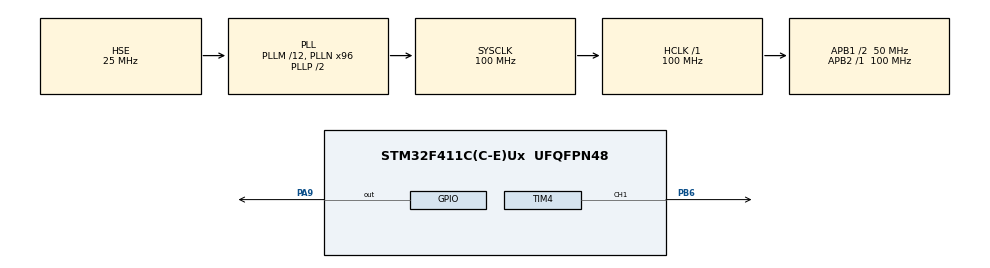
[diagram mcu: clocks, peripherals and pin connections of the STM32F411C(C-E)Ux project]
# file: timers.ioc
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Mcu.Family=STM32F4
Mcu.Name=STM32F411C(C-E)Ux
Mcu.Package=UFQFPN48
NVIC.PriorityGroup=NVIC_PRIORITYGROUP_4
NVIC.TIM2_IRQn=true\:0\:0\:false\:false\:true\:true\:true\:true
PA13.Mode=Serial_Wire
PA13.Signal=SYS_JTMS-SWDIO
PA14.Mode=Serial_Wire
PA14.Signal=SYS_JTCK-SWCLK
PA9.Signal=GPIO_Output
PB6.Signal=S_TIM4_CH1
PH0\ -\ OSC_IN.Mode=HSE-External-Oscillator
PH0\ -\ OSC_IN.Signal=RCC_OSC_IN
PH1\ -\ OSC_OUT.Mode=HSE-External-Oscillator
PH1\ -\ OSC_OUT.Signal=RCC_OSC_OUT
ProjectManager.HeapSize=0x200
ProjectManager.StackSize=0x400
ProjectManager.TargetToolchain=STM32CubeIDE
RCC.48MHZClocksFreq_Value=50000000
RCC.AHBFreq_Value=100000000
RCC.APB1CLKDivider=RCC_HCLK_DIV2
RCC.APB1Freq_Value=50000000
RCC.APB1TimFreq_Value=100000000
RCC.APB2Freq_Value=100000000
RCC.APB2TimFreq_Value=100000000
RCC.CortexFreq_Value=100000000
RCC.HCLKFreq_Value=100000000
RCC.HSE_VALUE=25000000
RCC.HSI_VALUE=16000000
RCC.LSE_VALUE=32768
RCC.PLLM=12
RCC.PLLN=96
RCC.PLLSourceVirtual=RCC_PLLSOURCE_HSE
RCC.SYSCLKFreq_VALUE=100000000
RCC.SYSCLKSource=RCC_SYSCLKSOURCE_PLLCLK
RCC.VCOOutputFreq_Value=200000000
SH.S_TIM4_CH1.0=TIM4_CH1,PWM Generation1 CH1
TIM2.Period=50000-1
TIM2.Prescaler=1000 -1 
TIM3.ClockDivision=TIM_CLOCKDIVISION_DIV1
TIM3.Prescaler=100-1
TIM4.Channel-PWM\ Generation1\ CH1=TIM_CHANNEL_1
TIM4.Period=50000-1
TIM4.Prescaler=4 - 1
VP_TIM2_VS_ClockSourceINT.Mode=Internal
VP_TIM3_VS_ClockSourceINT.Mode=Internal
VP_TIM4_VS_ClockSourceINT.Mode=Internal
board=custom

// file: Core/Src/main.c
/* USER CODE BEGIN Header */
/**
  ******************************************************************************
  * @file           : main.c
  * @brief          : Main program body
  ******************************************************************************
  * @attention
  *
  * Copyright (c) 2025 STMicroelectronics.
  * All rights reserved.
  *
  * This software is licensed under terms that can be found in the LICENSE file
  * in the root directory of this software component.
  * If no LICENSE file comes with this software, it is provided AS-IS.
  *
  ******************************************************************************
  */
/* USER CODE END Header */
#include "main.h"
#include<string.h>

TIM_HandleTypeDef htim2;
TIM_HandleTypeDef htim3;
TIM_HandleTypeDef htim4;

/* USER CODE BEGIN PV */
void delay_us(uint16_t time){
	__HAL_TIM_SET_COUNTER(&htim3,0);
	while(__HAL_TIM_GET_COUNTER(&htim3)<time);

}
void HAL_TIM_PeriodElapsedCallback(TIM_HandleTypeDef *htim){
	  if(htim->Instance == TIM2){
		  HAL_GPIO_TogglePin(GPIOA, GPIO_PIN_9);
	  }

 }

/* USER CODE END PV */

void SystemClock_Config(void);
static void MX_GPIO_Init(void);
static void MX_TIM2_Init(void);
static void MX_TIM3_Init(void);
static void MX_TIM4_Init(void);

/* USER CODE BEGIN 0 */
/* USER CODE BEGIN 2 */

/* USER CODE END 0 */

int main(void)
{

  /* MCU Configuration--------------------------------------------------------*/

  /* Reset of all peripherals, Initializes the Flash interface and the Systick. */
  HAL_Init();

  /* Configure the system clock */
  SystemClock_Config();

  /* Initialize all configured peripherals */
  MX_GPIO_Init();
  MX_TIM2_Init();
  MX_TIM3_Init();
  MX_TIM4_Init();
  HAL_TIM_PWM_Start(&htim4, TIM_CHANNEL_1);
  __HAL_TIM_SET_COMPARE(&htim4,TIM_CHANNEL_1,0);
  /* USER CODE BEGIN 2 */

/* USER CODE END 0 */

/**
  * @brief  The application entry point.
  * @retval int
  */
int main(void)
{

  /* USER CODE BEGIN 1 */

  /* USER CODE END 1 */

  /* MCU Configuration--------------------------------------------------------*/

  /* Reset of all peripherals, Initializes the Flash interface and the Systick. */
  HAL_Init();

  /* USER CODE BEGIN Init */

  /* USER CODE END Init */

  /* Configure the system clock */
  SystemClock_Config();

  /* USER CODE BEGIN SysInit */

  /* USER CODE END SysInit */

  /* Initialize all configured peripherals */
  MX_GPIO_Init();
  MX_TIM2_Init();
  MX_TIM3_Init();
  HAL_TIM_Base_Start(&htim3);
  /* USER CODE BEGIN 2 */
 void HAL_TIM_PeriodElapsedCallback(TIM_HandleTypeDef *htim){
	  if(htim->Instance == TIM2){
		  HAL_GPIO_TogglePin(GPIOA, GPIO_PIN_9);
	  }

 }

/* USER CODE END 0 */

/**
  * @brief  The application entry point.
  * @retval int
  */
int main(void)
{

  /* USER CODE BEGIN 1 */

  /* USER CODE END 1 */

  /* MCU Configuration--------------------------------------------------------*/

  /* Reset of all peripherals, Initializes the Flash interface and the Systick. */
  HAL_Init();

  /* USER CODE BEGIN Init */

  /* USER CODE END Init */

  /* Configure the system clock */
  SystemClock_Config();

  /* USER CODE BEGIN SysInit */

  /* USER CODE END SysInit */

  /* Initialize all configured peripherals */
  MX_GPIO_Init();
  MX_TIM2_Init();
  HAL_TIM_Base_Start_IT(&htim2);
uint16_t duty;

  /* USER CODE END 2 */

  /* Infinite loop */
  /* USER CODE BEGIN WHILE */
  while (1)
  {
	  while(duty<50000){
	  __HAL_TIM_SET_COMPARE(&htim4,TIM_CHANNEL_1,duty);
	  duty+=1000;
	  }
  while(duty >0){
	  __HAL_TIM_SET_COMPARE(&htim4,TIM_CHANNEL_1,duty);
			  duty-=1000;

  }

  }
  }
    /* USER CODE END WHILE */

  }
}

void SystemClock_Config(void)
{
  RCC_OscInitTypeDef RCC_OscInitStruct = {0};
  RCC_ClkInitTypeDef RCC_ClkInitStruct = {0};

  /** Configure the main internal regulator output voltage
  */
  __HAL_RCC_PWR_CLK_ENABLE();
  __HAL_PWR_VOLTAGESCALING_CONFIG(PWR_REGULATOR_VOLTAGE_SCALE1);

  /** Initializes the RCC Oscillators according to the specified parameters
  * in the RCC_OscInitTypeDef structure.
  */
  RCC_OscInitStruct.OscillatorType = RCC_OSCILLATORTYPE_HSE;
  RCC_OscInitStruct.HSEState = RCC_HSE_ON;
  RCC_OscInitStruct.PLL.PLLState = RCC_PLL_ON;
  RCC_OscInitStruct.PLL.PLLSource = RCC_PLLSOURCE_HSE;
  RCC_OscInitStruct.PLL.PLLM = 12;
  RCC_OscInitStruct.PLL.PLLN = 96;
  RCC_OscInitStruct.PLL.PLLP = RCC_PLLP_DIV2;
  RCC_OscInitStruct.PLL.PLLQ = 4;
  if (HAL_RCC_OscConfig(&RCC_OscInitStruct) != HAL_OK)
  {
    Error_Handler();
  }

  /** Initializes the CPU, AHB and APB buses clocks
  */
  RCC_ClkInitStruct.ClockType = RCC_CLOCKTYPE_HCLK|RCC_CLOCKTYPE_SYSCLK
                              |RCC_CLOCKTYPE_PCLK1|RCC_CLOCKTYPE_PCLK2;
  RCC_ClkInitStruct.SYSCLKSource = RCC_SYSCLKSOURCE_PLLCLK;
  RCC_ClkInitStruct.AHBCLKDivider = RCC_SYSCLK_DIV1;
  RCC_ClkInitStruct.APB1CLKDivider = RCC_HCLK_DIV2;
  RCC_ClkInitStruct.APB2CLKDivider = RCC_HCLK_DIV1;

  if (HAL_RCC_ClockConfig(&RCC_ClkInitStruct, FLASH_LATENCY_3) != HAL_OK)
  {
    Error_Handler();
  }
}

static void MX_TIM2_Init(void)
{

  TIM_ClockConfigTypeDef sClockSourceConfig = {0};
  TIM_MasterConfigTypeDef sMasterConfig = {0};

  htim2.Instance = TIM2;
  htim2.Init.Prescaler = 1000 -1 ;
  htim2.Init.CounterMode = TIM_COUNTERMODE_UP;
  htim2.Init.Period = 50000-1;
  htim2.Init.ClockDivision = TIM_CLOCKDIVISION_DIV1;
  htim2.Init.AutoReloadPreload = TIM_AUTORELOAD_PRELOAD_DISABLE;
  if (HAL_TIM_Base_Init(&htim2) != HAL_OK)
  {
    Error_Handler();
  }
  sClockSourceConfig.ClockSource = TIM_CLOCKSOURCE_INTERNAL;
  if (HAL_TIM_ConfigClockSource(&htim2, &sClockSourceConfig) != HAL_OK)
  {
    Error_Handler();
  }
  sMasterConfig.MasterOutputTrigger = TIM_TRGO_RESET;
  sMasterConfig.MasterSlaveMode = TIM_MASTERSLAVEMODE_DISABLE;
  if (HAL_TIMEx_MasterConfigSynchronization(&htim2, &sMasterConfig) != HAL_OK)
  {
    Error_Handler();
  }

}

static void MX_TIM3_Init(void)
{

  TIM_ClockConfigTypeDef sClockSourceConfig = {0};
  TIM_MasterConfigTypeDef sMasterConfig = {0};

  htim3.Instance = TIM3;
  htim3.Init.Prescaler = 100-1;
  htim3.Init.CounterMode = TIM_COUNTERMODE_UP;
  htim3.Init.Period = 65535;
  htim3.Init.ClockDivision = TIM_CLOCKDIVISION_DIV1;
  htim3.Init.AutoReloadPreload = TIM_AUTORELOAD_PRELOAD_DISABLE;
  if (HAL_TIM_Base_Init(&htim3) != HAL_OK)
  {
    Error_Handler();
  }
  sClockSourceConfig.ClockSource = TIM_CLOCKSOURCE_INTERNAL;
  if (HAL_TIM_ConfigClockSource(&htim3, &sClockSourceConfig) != HAL_OK)
  {
    Error_Handler();
  }
  sMasterConfig.MasterOutputTrigger = TIM_TRGO_RESET;
  sMasterConfig.MasterSlaveMode = TIM_MASTERSLAVEMODE_DISABLE;
  if (HAL_TIMEx_MasterConfigSynchronization(&htim3, &sMasterConfig) != HAL_OK)
  {
    Error_Handler();
  }

}

static void MX_TIM4_Init(void)
{

  TIM_ClockConfigTypeDef sClockSourceConfig = {0};
  TIM_MasterConfigTypeDef sMasterConfig = {0};
  TIM_OC_InitTypeDef sConfigOC = {0};

  htim4.Instance = TIM4;
  htim4.Init.Prescaler = 4 - 1;
  htim4.Init.CounterMode = TIM_COUNTERMODE_UP;
  htim4.Init.Period = 50000-1;
  htim4.Init.ClockDivision = TIM_CLOCKDIVISION_DIV1;
  htim4.Init.AutoReloadPreload = TIM_AUTORELOAD_PRELOAD_DISABLE;
  if (HAL_TIM_Base_Init(&htim4) != HAL_OK)
  {
    Error_Handler();
  }
  sClockSourceConfig.ClockSource = TIM_CLOCKSOURCE_INTERNAL;
  if (HAL_TIM_ConfigClockSource(&htim4, &sClockSourceConfig) != HAL_OK)
  {
    Error_Handler();
  }
  if (HAL_TIM_PWM_Init(&htim4) != HAL_OK)
  {
    Error_Handler();
  }
  sMasterConfig.MasterOutputTrigger = TIM_TRGO_RESET;
  sMasterConfig.MasterSlaveMode = TIM_MASTERSLAVEMODE_DISABLE;
  if (HAL_TIMEx_MasterConfigSynchronization(&htim4, &sMasterConfig) != HAL_OK)
  {
    Error_Handler();
  }
  sConfigOC.OCMode = TIM_OCMODE_PWM1;
  sConfigOC.Pulse = 0;
  sConfigOC.OCPolarity = TIM_OCPOLARITY_HIGH;
  sConfigOC.OCFastMode = TIM_OCFAST_DISABLE;
  if (HAL_TIM_PWM_ConfigChannel(&htim4, &sConfigOC, TIM_CHANNEL_1) != HAL_OK)
  {
    Error_Handler();
  }
  HAL_TIM_MspPostInit(&htim4);

}

static void MX_GPIO_Init(void)
{
  GPIO_InitTypeDef GPIO_InitStruct = {0};

  /* GPIO Ports Clock Enable */
  __HAL_RCC_GPIOH_CLK_ENABLE();
  __HAL_RCC_GPIOA_CLK_ENABLE();
  __HAL_RCC_GPIOB_CLK_ENABLE();

  /*Configure GPIO pin Output Level */
  HAL_GPIO_WritePin(GPIOA, GPIO_PIN_9, GPIO_PIN_RESET);

  /*Configure GPIO pin : PA9 */
  GPIO_InitStruct.Pin = GPIO_PIN_9;
  GPIO_InitStruct.Mode = GPIO_MODE_OUTPUT_PP;
  GPIO_InitStruct.Pull = GPIO_NOPULL;
  GPIO_InitStruct.Speed = GPIO_SPEED_FREQ_LOW;
  HAL_GPIO_Init(GPIOA, &GPIO_InitStruct);

}

void Error_Handler(void)
{
  __disable_irq();
  while (1)
  {
  }
}
